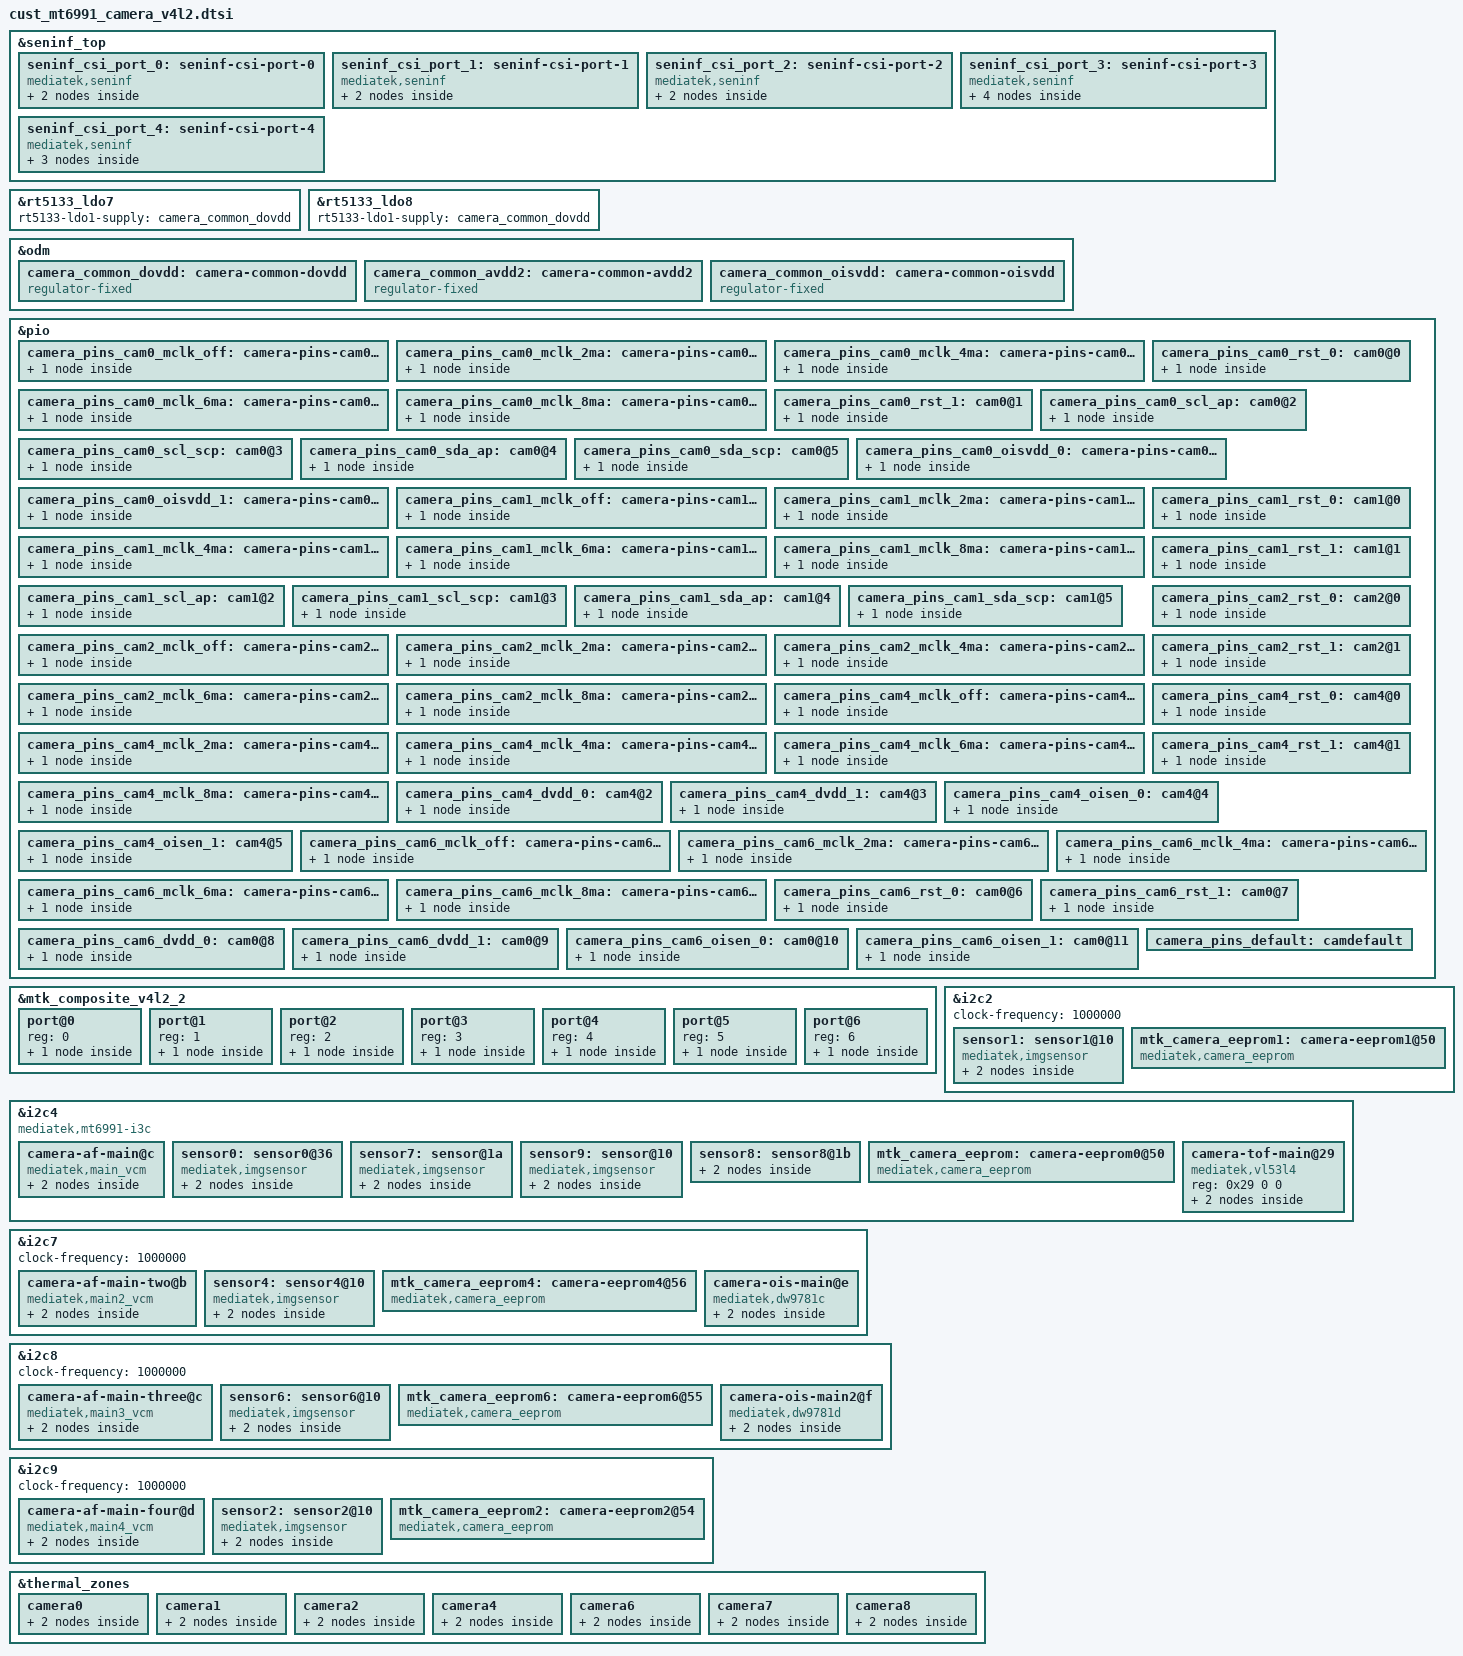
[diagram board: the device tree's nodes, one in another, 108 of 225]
// SPDX-License-Identifier: GPL-2.0
/* Copyright (c) 2023 MediaTek Inc. */
#include <dt-bindings/clock/mt6991-clk.h>

&seninf_top {
		seninf_csi_port_0: seninf-csi-port-0 {
			compatible = "mediatek,seninf";
			csi-port = "0";

			nvmem-cells = <&csi_efuse0>;
			nvmem-cell-names = "rg_csi";

			port {
				seninf_csi_port_0_in: endpoint {
					remote-endpoint = <&sensor1_out>;
				};
			};
		};

		seninf_csi_port_1: seninf-csi-port-1 {
			compatible = "mediatek,seninf";
			csi-port = "1";

			nvmem-cells = <&csi_efuse1>;
			nvmem-cell-names = "rg_csi";

			port {
				seninf_csi_port_1_in: endpoint {
					remote-endpoint = <&sensor6_out>;
				};
			};
		};

		seninf_csi_port_2: seninf-csi-port-2 {
			compatible = "mediatek,seninf";
			csi-port = "2";

			nvmem-cells = <&csi_efuse2>;
			nvmem-cell-names = "rg_csi";

			port {
				seninf_csi_port_2_in: endpoint {
					remote-endpoint = <&sensor4_out>;
				};
			};
		};
		seninf_csi_port_3: seninf-csi-port-3 {
			compatible = "mediatek,seninf";
			csi-port = "3";

			nvmem-cells = <&csi_efuse3>;
			nvmem-cell-names = "rg_csi";

			port {
				seninf_csi_port_3_in_1: endpoint@1 {
					remote-endpoint = <&sensor0_out>;
				};
				seninf_csi_port_3_in_2: endpoint@2 {
					remote-endpoint = <&sensor7_out>;
				};
				seninf_csi_port_3_in_3: endpoint@3 {
					remote-endpoint = <&sensor9_out>;
				};
			};
		};
		seninf_csi_port_4: seninf-csi-port-4 {
			compatible = "mediatek,seninf";
			csi-port = "4";

			nvmem-cells = <&csi_efuse4>;
			nvmem-cell-names = "rg_csi";

			port {
				seninf_csi_port_4_in_1: endpoint@1 {
					remote-endpoint = <&sensor2_out>;
				};
				seninf_csi_port_4_in_2: endpoint@2 {
					remote-endpoint = <&sensor8_out>;
				};
			};
		};
};

&rt5133_ldo7 {
	rt5133-ldo1-supply = <&camera_common_dovdd>;
};

&rt5133_ldo8 {
	rt5133-ldo1-supply = <&camera_common_dovdd>;
};

/* CAMERA GPIO fixed to regulator */
&odm {
	camera_common_dovdd: camera-common-dovdd {
		compatible = "regulator-fixed";
		regulator-name = "camera-common-dovdd";
		regulator-min-microvolt = <1800000>;
		regulator-max-microvolt = <1800000>;
		enable-active-high;
		gpio = <&pio 213 0x0>;
	};
	camera_common_avdd2: camera-common-avdd2 {
		compatible = "regulator-fixed";
		regulator-name = "camera-common-avdd2";
		regulator-min-microvolt = <1800000>;
		regulator-max-microvolt = <1800000>;
		enable-active-high;
		/*gpio = <&pio 92 0x0>;*/
	};
	camera_common_oisvdd: camera-common-oisvdd {
		compatible = "regulator-fixed";
		regulator-name = "camera-common-oisvdd";
		regulator-min-microvolt = <1800000>;
		regulator-max-microvolt = <1800000>;
		enable-active-high;
		/*gpio = <&pio 113 0x0>;*/
	};
};

/* CAMERA GPIO standardization */
&pio {
	camera_pins_cam0_mclk_off: camera-pins-cam0-mclk-off {
		pins-cmd-dat {
			pinmux = <PINMUX_GPIO79__FUNC_GPIO79>;
			drive-strength = <1>;
		};
	};
	camera_pins_cam0_mclk_2ma: camera-pins-cam0-mclk-2ma {
		pins-cmd-dat {
			pinmux = <PINMUX_GPIO79__FUNC_CMMCLK0>;
			drive-strength = <0>;
		};
	};
	camera_pins_cam0_mclk_4ma: camera-pins-cam0-mclk-4ma {
		pins-cmd-dat {
			pinmux = <PINMUX_GPIO79__FUNC_CMMCLK0>;
			drive-strength = <1>;
		};
	};
	camera_pins_cam0_mclk_6ma: camera-pins-cam0-mclk-6ma {
		pins-cmd-dat {
			pinmux = <PINMUX_GPIO79__FUNC_CMMCLK0>;
			drive-strength = <2>;
		};
	};
	camera_pins_cam0_mclk_8ma: camera-pins-cam0-mclk-8ma {
		pins-cmd-dat {
			pinmux = <PINMUX_GPIO79__FUNC_CMMCLK0>;
			drive-strength = <3>;
		};
	};
	camera_pins_cam0_rst_0: cam0@0 {
		pins-cmd-dat {
			pinmux = <PINMUX_GPIO187__FUNC_GPIO187>;
			slew-rate = <1>;
			output-low;
		};
	};
	camera_pins_cam0_rst_1: cam0@1 {
		pins-cmd-dat {
			pinmux = <PINMUX_GPIO187__FUNC_GPIO187>;
			slew-rate = <1>;
			output-high;
		};
	};
	camera_pins_cam0_scl_ap: cam0@2 {
		pins-cmd-dat {
			pinmux = <PINMUX_GPIO190__FUNC_SCL4>;
		};
	};
	camera_pins_cam0_scl_scp: cam0@3 {
		pins-cmd-dat {
			pinmux = <PINMUX_GPIO190__FUNC_SCP_SCL9>;
		};
	};
	camera_pins_cam0_sda_ap: cam0@4 {
		pins-cmd-dat {
			pinmux = <PINMUX_GPIO191__FUNC_SDA4>;
		};
	};
	camera_pins_cam0_sda_scp: cam0@5 {
		pins-cmd-dat {
			pinmux = <PINMUX_GPIO191__FUNC_SCP_SDA9>;
		};
	};
	camera_pins_cam0_oisvdd_0: camera-pins-cam0-oisvdd-0 {
		pins-cmd-dat {
#if 0
			pinmux = <PINMUX_GPIO93__FUNC_GPIO93>;
			slew-rate = <1>;
			output-low;
#endif
		};
	};
	camera_pins_cam0_oisvdd_1: camera-pins-cam0-oisvdd-1 {
		pins-cmd-dat {
#if 0
			pinmux = <PINMUX_GPIO93__FUNC_GPIO93>;
			slew-rate = <1>;
			output-high;
#endif
		};
	};
	camera_pins_cam1_mclk_off: camera-pins-cam1-mclk-off {
		pins-cmd-dat {
			pinmux = <PINMUX_GPIO80__FUNC_GPIO80>;
			drive-strength = <1>;
		};
	};
	camera_pins_cam1_mclk_2ma: camera-pins-cam1-mclk-2ma {
		pins-cmd-dat {
			pinmux = <PINMUX_GPIO80__FUNC_CMMCLK1>;
			drive-strength = <0>;
		};
	};
	camera_pins_cam1_mclk_4ma: camera-pins-cam1-mclk-4ma {
		pins-cmd-dat {
			pinmux = <PINMUX_GPIO80__FUNC_CMMCLK1>;
			drive-strength = <1>;
		};
	};
	camera_pins_cam1_mclk_6ma: camera-pins-cam1-mclk-6ma {
		pins-cmd-dat {
			pinmux = <PINMUX_GPIO80__FUNC_CMMCLK1>;
			drive-strength = <2>;
		};
	};
	camera_pins_cam1_mclk_8ma: camera-pins-cam1-mclk-8ma {
		pins-cmd-dat {
			pinmux = <PINMUX_GPIO80__FUNC_CMMCLK1>;
			drive-strength = <3>;
		};
	};
	camera_pins_cam1_rst_0: cam1@0 {
		pins-cmd-dat {
			pinmux = <PINMUX_GPIO186__FUNC_GPIO186>;
			slew-rate = <1>;
			output-low;
		};
	};
	camera_pins_cam1_rst_1: cam1@1 {
		pins-cmd-dat {
			pinmux = <PINMUX_GPIO186__FUNC_GPIO186>;
			slew-rate = <1>;
			output-high;
		};
	};
	camera_pins_cam1_scl_ap: cam1@2 {
		pins-cmd-dat {
			pinmux = <PINMUX_GPIO188__FUNC_SCL2>;
		};
	};
	camera_pins_cam1_scl_scp: cam1@3 {
		pins-cmd-dat {
			pinmux = <PINMUX_GPIO188__FUNC_SCP_SCL8>;
		};
	};
	camera_pins_cam1_sda_ap: cam1@4 {
		pins-cmd-dat {
			pinmux = <PINMUX_GPIO189__FUNC_SDA2>;
		};
	};
	camera_pins_cam1_sda_scp: cam1@5 {
		pins-cmd-dat {
			pinmux = <PINMUX_GPIO189__FUNC_SCP_SDA8>;
		};
	};
	camera_pins_cam2_mclk_off: camera-pins-cam2-mclk-off {
		pins-cmd-dat {
			pinmux = <PINMUX_GPIO210__FUNC_GPIO210>;
			drive-strength = <1>;
		};
	};
	camera_pins_cam2_mclk_2ma: camera-pins-cam2-mclk-2ma {
		pins-cmd-dat {
			pinmux = <PINMUX_GPIO210__FUNC_CMMCLK4>;
			drive-strength = <0>;
		};
	};
	camera_pins_cam2_mclk_4ma: camera-pins-cam2-mclk-4ma {
		pins-cmd-dat {
			pinmux = <PINMUX_GPIO210__FUNC_CMMCLK4>;
			drive-strength = <1>;
		};
	};
	camera_pins_cam2_mclk_6ma: camera-pins-cam2-mclk-6ma {
		pins-cmd-dat {
			pinmux = <PINMUX_GPIO210__FUNC_CMMCLK4>;
			drive-strength = <2>;
		};
	};
	camera_pins_cam2_mclk_8ma: camera-pins-cam2-mclk-8ma {
		pins-cmd-dat {
			pinmux = <PINMUX_GPIO210__FUNC_CMMCLK4>;
			drive-strength = <3>;
		};
	};
	camera_pins_cam2_rst_0: cam2@0 {
		pins-cmd-dat {
#if 0
			pinmux = <PINMUX_GPIO206__FUNC_GPIO206>;
			slew-rate = <1>;
			output-low;
#endif
		};
	};
	camera_pins_cam2_rst_1: cam2@1 {
		pins-cmd-dat {
#if 0
			pinmux = <PINMUX_GPIO206__FUNC_GPIO206>;
			slew-rate = <1>;
			output-high;
#endif
		};
	};
#if 0
	camera_pins_cam2_mclk1_off: camera-pins-cam2-mclk1-off {
		pins-cmd-dat {
			pinmux = <PINMUX_GPIO124__FUNC_GPIO124>;
			drive-strength = <1>;
		};
	};
	camera_pins_cam2_mclk1_2ma: camera-pins-cam2-mclk1-2ma {
		pins-cmd-dat {
			pinmux = <PINMUX_GPIO124__FUNC_CMMCLK0>;
			drive-strength = <0>;
		};
	};
	camera_pins_cam2_mclk1_4ma: camera-pins-cam2-mclk1-4ma {
		pins-cmd-dat {
			pinmux = <PINMUX_GPIO124__FUNC_CMMCLK0>;
			drive-strength = <1>;
		};
	};
	camera_pins_cam2_mclk1_6ma: camera-pins-cam2-mclk1-6ma {
		pins-cmd-dat {
			pinmux = <PINMUX_GPIO124__FUNC_CMMCLK0>;
			drive-strength = <2>;
		};
	};
	camera_pins_cam2_mclk1_8ma: camera-pins-cam2-mclk1-8ma {
		pins-cmd-dat {
			pinmux = <PINMUX_GPIO124__FUNC_CMMCLK0>;
			drive-strength = <3>;
		};
	};
	camera_pins_cam2_rst1_0: cam2@2 {
		pins-cmd-dat {
			pinmux = <PINMUX_GPIO160__FUNC_GPIO160>;
			slew-rate = <1>;
			output-low;
		};
	};
	camera_pins_cam2_rst1_1: cam2@3 {
		pins-cmd-dat {
			pinmux = <PINMUX_GPIO160__FUNC_GPIO160>;
			slew-rate = <1>;
			output-high;
		};
	};
	camera_pins_cam2_ponv_0: cam2@4 {
		pins-cmd-dat {
			pinmux = <PINMUX_GPIO159__FUNC_GPIO159>;
			slew-rate = <1>;
			output-low;
		};
	};
	camera_pins_cam2_ponv_1: cam2@5 {
		pins-cmd-dat {
			pinmux = <PINMUX_GPIO159__FUNC_GPIO159>;
			slew-rate = <1>;
			output-high;
		};
	};
	camera_pins_cam2_scl_ap: cam2@6 {
		pins-cmd-dat {
			pinmux = <PINMUX_GPIO104__FUNC_SCL13>;
		};
	};
	camera_pins_cam2_scl_scp: cam2@7 {
		pins-cmd-dat {
			pinmux = <PINMUX_GPIO104__FUNC_SCP_SCL3>;
		};
	};
	camera_pins_cam2_sda_ap: cam2@8 {
		pins-cmd-dat {
			pinmux = <PINMUX_GPIO105__FUNC_SDA13>;
		};
	};
	camera_pins_cam2_sda_scp: cam2@9 {
		pins-cmd-dat {
			pinmux = <PINMUX_GPIO105__FUNC_SCP_SDA3>;
		};
	};
	camera_pins_cam2_eint: cam2@10 {
		pins-cmd-dat {
			pinmux = <PINMUX_GPIO109__FUNC_GPIO109>;
			bias-pull-up;
			input-enable;
		};
	};
#endif
	camera_pins_cam4_mclk_off: camera-pins-cam4-mclk-off {
		pins-cmd-dat {
			pinmux = <PINMUX_GPIO192__FUNC_GPIO192>;
			drive-strength = <1>;
		};
	};
	camera_pins_cam4_mclk_2ma: camera-pins-cam4-mclk-2ma {
		pins-cmd-dat {
			pinmux = <PINMUX_GPIO192__FUNC_CMMCLK2>;
			drive-strength = <0>;
		};
	};
	camera_pins_cam4_mclk_4ma: camera-pins-cam4-mclk-4ma {
		pins-cmd-dat {
			pinmux = <PINMUX_GPIO192__FUNC_CMMCLK2>;
			drive-strength = <1>;
		};
	};
	camera_pins_cam4_mclk_6ma: camera-pins-cam4-mclk-6ma {
		pins-cmd-dat {
			pinmux = <PINMUX_GPIO192__FUNC_CMMCLK2>;
			drive-strength = <2>;
		};
	};
	camera_pins_cam4_mclk_8ma: camera-pins-cam4-mclk-8ma {
		pins-cmd-dat {
			pinmux = <PINMUX_GPIO192__FUNC_CMMCLK2>;
			drive-strength = <3>;
		};
	};
	camera_pins_cam4_rst_0: cam4@0 {
		pins-cmd-dat {
#if 0
			pinmux = <PINMUX_GPIO193__FUNC_GPIO193>;
			slew-rate = <1>;
			output-low;
#endif
		};
	};
	camera_pins_cam4_rst_1: cam4@1 {
		pins-cmd-dat {
#if 0
			pinmux = <PINMUX_GPIO193__FUNC_GPIO193>;
			slew-rate = <1>;
			output-high;
#endif
		};
	};
	camera_pins_cam4_dvdd_0: cam4@2 {
		pins-cmd-dat {
#if 0
			pinmux = <PINMUX_GPIO112__FUNC_GPIO112>;
			slew-rate = <1>;
			output-low;
#endif
		};
	};
	camera_pins_cam4_dvdd_1: cam4@3 {
		pins-cmd-dat {
#if 0
			pinmux = <PINMUX_GPIO112__FUNC_GPIO112>;
			slew-rate = <1>;
			output-high;
#endif
		};
	};
	camera_pins_cam4_oisen_0: cam4@4 {
		pins-cmd-dat {
#if 0
			pinmux = <PINMUX_GPIO212__FUNC_GPIO212>;
			slew-rate = <1>;
			output-low;
#endif
		};
	};
	camera_pins_cam4_oisen_1: cam4@5 {
		pins-cmd-dat {
#if 0
			pinmux = <PINMUX_GPIO212__FUNC_GPIO212>;
			slew-rate = <1>;
			output-high;
#endif
		};
	};
	camera_pins_cam6_mclk_off: camera-pins-cam6-mclk-off {
		pins-cmd-dat {
			pinmux = <PINMUX_GPIO196__FUNC_GPIO196>;
			drive-strength = <1>;
		};
	};
	camera_pins_cam6_mclk_2ma: camera-pins-cam6-mclk-2ma {
		pins-cmd-dat {
			pinmux = <PINMUX_GPIO196__FUNC_CMMCLK3>;
			drive-strength = <0>;
		};
	};
	camera_pins_cam6_mclk_4ma: camera-pins-cam6-mclk-4ma {
		pins-cmd-dat {
			pinmux = <PINMUX_GPIO196__FUNC_CMMCLK3>;
			drive-strength = <1>;
		};
	};
	camera_pins_cam6_mclk_6ma: camera-pins-cam6-mclk-6ma {
		pins-cmd-dat {
			pinmux = <PINMUX_GPIO196__FUNC_CMMCLK3>;
			drive-strength = <2>;
		};
	};
	camera_pins_cam6_mclk_8ma: camera-pins-cam6-mclk-8ma {
		pins-cmd-dat {
			pinmux = <PINMUX_GPIO196__FUNC_CMMCLK3>;
			drive-strength = <3>;
		};
	};
	camera_pins_cam6_rst_0: cam0@6 {
		pins-cmd-dat {
#if 0
			pinmux = <PINMUX_GPIO197__FUNC_GPIO197>;
			slew-rate = <1>;
			output-low;
#endif
		};
	};
	camera_pins_cam6_rst_1: cam0@7 {
		pins-cmd-dat {
#if 0
			pinmux = <PINMUX_GPIO197__FUNC_GPIO197>;
			slew-rate = <1>;
			output-high;
#endif
		};
	};
	camera_pins_cam6_dvdd_0: cam0@8 {
		pins-cmd-dat {
#if 0
			pinmux = <PINMUX_GPIO111__FUNC_GPIO111>;
			slew-rate = <1>;
			output-low;
#endif
		};
	};
	camera_pins_cam6_dvdd_1: cam0@9 {
		pins-cmd-dat {
#if 0
			pinmux = <PINMUX_GPIO111__FUNC_GPIO111>;
			slew-rate = <1>;
			output-high;
#endif
		};
	};
	camera_pins_cam6_oisen_0: cam0@10 {
		pins-cmd-dat {
#if 0
			pinmux = <PINMUX_GPIO185__FUNC_GPIO185>;
			slew-rate = <1>;
			output-low;
#endif
		};
	};
	camera_pins_cam6_oisen_1: cam0@11 {
		pins-cmd-dat {
#if 0
			pinmux = <PINMUX_GPIO185__FUNC_GPIO185>;
			slew-rate = <1>;
			output-high;
#endif
		};
	};
	camera_pins_default: camdefault {
	};
};
/* CAMERA GPIO end */
&mtk_composite_v4l2_2 {
	#address-cells = <1>;
	#size-cells = <0>;
	port@0 {
		reg = <0>;
		main_af_endpoint: endpoint {
			remote-endpoint = <&main_af>;
		};
	};
	port@1 {
		reg = <1>;
		main_af_cam1_endpoint: endpoint {
			remote-endpoint = <&main_af_cam1>;
		};
	};
	port@2 {
		reg = <2>;
		main_af_cam2_endpoint: endpoint {
			remote-endpoint = <&main_af_cam2>;
		};
	};
	port@3 {
		reg = <3>;
		main_af_cam3_endpoint: endpoint {
			remote-endpoint = <&main_af_cam3>;
		};
	};
	port@4 {
		reg = <4>;
		main_ois_cam1_endpoint: endpoint {
			remote-endpoint = <&main_ois_cam1>;
		};
	};
	port@5 {
		reg = <5>;
		main_ois_cam2_endpoint: endpoint {
			remote-endpoint = <&main_ois_cam2>;
		};
	};
	port@6 {
		reg = <6>;
		main_tof_endpoint: endpoint {
			remote-endpoint = <&main_tof>;
		};
	};
};

&i2c2 {
	status = "okay";
	clock-frequency = <1000000>;

	sensor1: sensor1@10 {
		compatible = "mediatek,imgsensor";
		sensor-names = "s5k3p9sp_mipi_raw";
		reg = <0x10>;
		maximum-pmic-delay = <4000>;

		#thermal-sensor-cells = <0>;

		pinctrl-names = "mclk_off",
				"mclk_2mA",
				"mclk_4mA",
				"mclk_6mA",
				"mclk_8mA",
				"rst_low",
				"rst_high",
				"scl_ap",
				"scl_scp",
				"sda_ap",
				"sda_scp";
		pinctrl-0 = <&camera_pins_cam1_mclk_off>;
		pinctrl-1 = <&camera_pins_cam1_mclk_2ma>;
		pinctrl-2 = <&camera_pins_cam1_mclk_4ma>;
		pinctrl-3 = <&camera_pins_cam1_mclk_6ma>;
		pinctrl-4 = <&camera_pins_cam1_mclk_8ma>;
		pinctrl-5 = <&camera_pins_cam1_rst_0>;
		pinctrl-6 = <&camera_pins_cam1_rst_1>;
		pinctrl-7 = <&camera_pins_cam1_scl_ap>;
		pinctrl-8 = <&camera_pins_cam1_scl_scp>;
		pinctrl-9 = <&camera_pins_cam1_sda_ap>;
		pinctrl-10 = <&camera_pins_cam1_sda_scp>;

		avdd-supply = <&rt5133_ldo3>;
		dvdd1-supply = <&rt5133_gpio3>;
		dovdd-supply = <&camera_common_dovdd>;
		base-supply = <&rt5133_base>;

		clocks = <&cksys_clk CLK_CK_UNIVPLL_192M_D32>,
			<&cksys_clk CLK_CK_UNIVPLL_192M_D16>,
			<&cksys_clk CLK_CK_F26M_CK_D2>,
			<&cksys_clk CLK_CK_UNIVPLL_192M_D10>,
			<&cksys_clk CLK_CK_UNIVPLL_192M_D8>,
			<&cksys_clk CLK_CK_UNIVPLL_D6_D16>,
			<&cksys_clk CLK_CK_OSC3>,
			<&cksys_clk CLK_CK_UNIVPLL_D6_D8>,
			<&vlp_cksys_clk CLK_VLP_CK_CAMTG1_SEL>;
		clock-names = "6", "12", "13", "19.2", "24", "26", "26_ulposc", "52", "mclk";

		status = "okay";
		port {
			sensor1_out: endpoint {
				remote-endpoint = <&seninf_csi_port_0_in>;
			};
		};
	};

	mtk_camera_eeprom1:camera-eeprom1@50 {
		compatible = "mediatek,camera_eeprom";
		reg = <0x50 0 0>;
		names = "s5k3p9sp_mtk_eeprom";
		status = "okay";
	};
};

&i2c4 {
	compatible = "mediatek,mt6991-i3c";
	#address-cells = <1>;
	#size-cells = <2>;
	status = "okay";

	camera-af-main@c {
		compatible = "mediatek,main_vcm";
		reg = <0x0c 0 0>;
		vin-supply = <&rt5133_gpio1>;
		port {
			main_af: endpoint {
				remote-endpoint = <&main_af_endpoint>;
			};
		};
	};

	sensor0: sensor0@36 {
		compatible = "mediatek,imgsensor";
		sensor-names = "ov48b_mipi_raw",
					"imx06a_mipi_raw";
		reg = <0x36 0 0>;
		maximum-pmic-delay = <4000>;

		#thermal-sensor-cells = <0>;

		pinctrl-names = "mclk_off",
				"mclk_2mA",
				"mclk_4mA",
				"mclk_6mA",
				"mclk_8mA",
				"rst_low",
				"rst_high",
				"scl_ap",
				"scl_scp",
				"sda_ap",
				"sda_scp",
				"oisvdd_off",
				"oisvdd_on";
		pinctrl-0 = <&camera_pins_cam0_mclk_off>;
		pinctrl-1 = <&camera_pins_cam0_mclk_2ma>;
		pinctrl-2 = <&camera_pins_cam0_mclk_4ma>;
		pinctrl-3 = <&camera_pins_cam0_mclk_6ma>;
		pinctrl-4 = <&camera_pins_cam0_mclk_8ma>;
		pinctrl-5 = <&camera_pins_cam0_rst_0>;
		pinctrl-6 = <&camera_pins_cam0_rst_1>;
		pinctrl-7 = <&camera_pins_cam0_scl_ap>;
		pinctrl-8 = <&camera_pins_cam0_scl_scp>;
		pinctrl-9 = <&camera_pins_cam0_sda_ap>;
		pinctrl-10 = <&camera_pins_cam0_sda_scp>;
		pinctrl-11 = <&camera_pins_cam0_oisvdd_0>;
		pinctrl-12 = <&camera_pins_cam0_oisvdd_1>;

		avdd-supply = <&rt5133_ldo5>;
		avdd2-supply = <&camera_common_avdd2>;
		dvdd-supply = <&rt5133_ldo8>;
		afvdd1-supply = <&rt5133_gpio1>;
		dovdd-supply = <&camera_common_dovdd>;
		base-supply = <&rt5133_base>;

		clocks = <&cksys_clk CLK_CK_UNIVPLL_192M_D32>,
			<&cksys_clk CLK_CK_UNIVPLL_192M_D16>,
			<&cksys_clk CLK_CK_F26M_CK_D2>,
			<&cksys_clk CLK_CK_UNIVPLL_192M_D10>,
			<&cksys_clk CLK_CK_UNIVPLL_192M_D8>,
			<&cksys_clk CLK_CK_UNIVPLL_D6_D16>,
			<&cksys_clk CLK_CK_OSC3>,
			<&cksys_clk CLK_CK_UNIVPLL_D6_D8>,
			<&vlp_cksys_clk CLK_VLP_CK_CAMTG0_SEL>;
		clock-names = "6", "12", "13", "19.2", "24", "26", "26_ulposc", "52", "mclk";

		status = "okay";
		port {
			sensor0_out: endpoint {
				remote-endpoint = <&seninf_csi_port_3_in_1>;
			};
		};
	};

	sensor7: sensor@1a {
		compatible = "mediatek,imgsensor";
		sensor-names = "imx989_mipi_raw";
		reindex-match = "imx989_mipi_raw";
		reg = <0x1a 0 0>;
		maximum-pmic-delay = <4000>;
		reindex-to = <0>;

		#thermal-sensor-cells = <0>;

		pinctrl-names = "mclk_off",
				"mclk_2mA",
				"mclk_4mA",
				"mclk_6mA",
				"mclk_8mA",
				"rst_low",
				"rst_high",
				"scl_ap",
				"scl_scp",
				"sda_ap",
				"sda_scp",
				"oisvdd_off",
				"oisvdd_on";
		pinctrl-0 = <&camera_pins_cam0_mclk_off>;
		pinctrl-1 = <&camera_pins_cam0_mclk_2ma>;
		pinctrl-2 = <&camera_pins_cam0_mclk_4ma>;
		pinctrl-3 = <&camera_pins_cam0_mclk_6ma>;
		pinctrl-4 = <&camera_pins_cam0_mclk_8ma>;
		pinctrl-5 = <&camera_pins_cam0_rst_0>;
		pinctrl-6 = <&camera_pins_cam0_rst_1>;
		pinctrl-7 = <&camera_pins_cam0_scl_ap>;
		pinctrl-8 = <&camera_pins_cam0_scl_scp>;
		pinctrl-9 = <&camera_pins_cam0_sda_ap>;
		pinctrl-10 = <&camera_pins_cam0_sda_scp>;
		pinctrl-11 = <&camera_pins_cam0_oisvdd_0>;
		pinctrl-12 = <&camera_pins_cam0_oisvdd_1>;

		avdd-supply = <&rt5133_ldo5>;
		avdd2-supply = <&camera_common_avdd2>;
		dvdd-supply = <&rt5133_ldo8>;
		afvdd1-supply = <&rt5133_gpio1>;
		dovdd-supply = <&camera_common_dovdd>;
		base-supply = <&rt5133_base>;

		clocks = <&cksys_clk CLK_CK_UNIVPLL_192M_D32>,
			<&cksys_clk CLK_CK_UNIVPLL_192M_D16>,
			<&cksys_clk CLK_CK_F26M_CK_D2>,
			<&cksys_clk CLK_CK_UNIVPLL_192M_D10>,
			<&cksys_clk CLK_CK_UNIVPLL_192M_D8>,
			<&cksys_clk CLK_CK_UNIVPLL_D6_D16>,
			<&cksys_clk CLK_CK_UNIVPLL_D6_D8>,
			<&vlp_cksys_clk CLK_VLP_CK_CAMTG0_SEL>;
		clock-names = "6", "12", "13", "19.2", "24", "26", "52", "mclk";

		status = "okay";
		port {
			sensor7_out: endpoint {
				remote-endpoint = <&seninf_csi_port_3_in_2>;
			};
		};
	};

	sensor9: sensor@10 {
		compatible = "mediatek,imgsensor";
		sensor-names = "s5khp3sp_mipi_raw";
		reindex-match = "s5khp3sp_mipi_raw";
		reg = <0x10 0 0>;
		maximum-pmic-delay = <4000>;
		reindex-to = <0>;

		#thermal-sensor-cells = <0>;

		pinctrl-names = "mclk_off",
				"mclk_2mA",
				"mclk_4mA",
				"mclk_6mA",
				"mclk_8mA",
				"rst_low",
				"rst_high",
				"scl_ap",
				"scl_scp",
				"sda_ap",
				"sda_scp",
				"oisvdd_off",
				"oisvdd_on";
		pinctrl-0 = <&camera_pins_cam0_mclk_off>;
		pinctrl-1 = <&camera_pins_cam0_mclk_2ma>;
		pinctrl-2 = <&camera_pins_cam0_mclk_4ma>;
		pinctrl-3 = <&camera_pins_cam0_mclk_6ma>;
		pinctrl-4 = <&camera_pins_cam0_mclk_8ma>;
		pinctrl-5 = <&camera_pins_cam0_rst_0>;
		pinctrl-6 = <&camera_pins_cam0_rst_1>;
		pinctrl-7 = <&camera_pins_cam0_scl_ap>;
		pinctrl-8 = <&camera_pins_cam0_scl_scp>;
		pinctrl-9 = <&camera_pins_cam0_sda_ap>;
		pinctrl-10 = <&camera_pins_cam0_sda_scp>;
		pinctrl-11 = <&camera_pins_cam0_oisvdd_0>;
		pinctrl-12 = <&camera_pins_cam0_oisvdd_1>;

		avdd-supply = <&rt5133_ldo5>;
		avdd2-supply = <&camera_common_avdd2>;
		dvdd-supply = <&rt5133_ldo8>;
		afvdd1-supply = <&rt5133_gpio1>;
		dovdd-supply = <&camera_common_dovdd>;
		base-supply = <&rt5133_base>;

		clocks = <&cksys_clk CLK_CK_UNIVPLL_192M_D32>,
			<&cksys_clk CLK_CK_UNIVPLL_192M_D16>,
			<&cksys_clk CLK_CK_F26M_CK_D2>,
			<&cksys_clk CLK_CK_UNIVPLL_192M_D10>,
			<&cksys_clk CLK_CK_UNIVPLL_192M_D8>,
			<&cksys_clk CLK_CK_UNIVPLL_D6_D16>,
			<&cksys_clk CLK_CK_UNIVPLL_D6_D8>,
			<&vlp_cksys_clk CLK_VLP_CK_CAMTG0_SEL>;
		clock-names = "6", "12", "13", "19.2", "24", "26", "52", "mclk";

		status = "okay";
		port {
			sensor9_out: endpoint {
				remote-endpoint = <&seninf_csi_port_3_in_3>;
			};
		};
	};

	sensor8: sensor8@1b {
		sensor-names = "imx866rgb_mipi_raw";
		reg = <0x1b 0x0360 0x08660000>;
		assigned-address = <0x25>;
		reindex-match = "imx866rgb_mipi_raw";
		reindex-to = <0>;
		maximum-pmic-delay = <4000>;
		#thermal-sensor-cells = <0>;

		pinctrl-names = "mclk_off",
				"mclk_2mA",
				"mclk_4mA",
				"mclk_6mA",
				"mclk_8mA",
				"rst_low",
				"rst_high";
		pinctrl-0 = <&camera_pins_cam2_mclk_off>;
		pinctrl-1 = <&camera_pins_cam2_mclk_2ma>;
		pinctrl-2 = <&camera_pins_cam2_mclk_4ma>;
		pinctrl-3 = <&camera_pins_cam2_mclk_6ma>;
		pinctrl-4 = <&camera_pins_cam2_mclk_8ma>;
		pinctrl-5 = <&camera_pins_cam2_rst_0>;
		pinctrl-6 = <&camera_pins_cam2_rst_1>;

		avdd-supply = <&rt5133_ldo6>; // AVDD for imx598/imx709
		avdd3-supply = <&camera_common_avdd2>; // AVDD2 for imx866
		avdd4-supply = <&rt5133_gpio2>; // AVDD2 for imx598
		dvdd-supply = <&rt5133_ldo7>; // DVDD for imx598
		dvdd2-supply = <&rt5133_ldo8>; // DVDD for imx709
		afvdd-supply = <&rt5133_ldo2>;
		dovdd-supply = <&camera_common_dovdd>;
		base-supply = <&rt5133_base>;

		clocks = <&cksys_clk CLK_CK_UNIVPLL_192M_D32>,
			<&cksys_clk CLK_CK_UNIVPLL_192M_D16>,
			<&cksys_clk CLK_CK_F26M_CK_D2>,
			<&cksys_clk CLK_CK_UNIVPLL_192M_D10>,
			<&cksys_clk CLK_CK_UNIVPLL_192M_D8>,
			<&cksys_clk CLK_CK_UNIVPLL_D6_D16>,
			<&cksys_clk CLK_CK_UNIVPLL_D6_D8>,
			<&vlp_cksys_clk CLK_VLP_CK_CAMTG4_SEL>;
		clock-names = "6", "12", "13", "19.2", "24", "26", "52", "mclk";
		status = "okay";
		port {
			sensor8_out: endpoint {
				remote-endpoint = <&seninf_csi_port_4_in_2>;
			};
		};
	};

	mtk_camera_eeprom:camera-eeprom0@50 {
		compatible = "mediatek,camera_eeprom";
		reg = <0x50 0 0>;
		names = "imx989_cust_eeprom",
				"ov48b_mtk_eeprom";
		status = "okay";
	};

	camera-tof-main@29 {
		compatible = "mediatek,vl53l4";
		reg = <0x29 0 0>;
		port {
			main_tof: endpoint {
				remote-endpoint = <&main_tof_endpoint>;
			};
		};
	};
};

&i2c7 {
	status = "okay";
	clock-frequency = <1000000>;

	camera-af-main-two@b {
		compatible = "mediatek,main2_vcm";
		reg = <0x0b>;
		vin-supply = <&rt5133_ldo2>;
		port {
			main_af_cam1: endpoint {
				remote-endpoint = <&main_af_cam1_endpoint>;
			};
		};
	};

	sensor4: sensor4@10 {
		compatible = "mediatek,imgsensor";
		sensor-names = "imx758_mipi_raw",
					"imx858_mipi_raw";
		reg = <0x10>;
		maximum-pmic-delay = <4000>;

		#thermal-sensor-cells = <0>;

		pinctrl-names = "mclk_off",
				"mclk_2mA",
				"mclk_4mA",
				"mclk_6mA",
				"mclk_8mA",
				"rst_low",
				"rst_high",
				"dvdd_off",
				"dvdd_on",
				"oisen_off",
				"oisen_on";
		pinctrl-0 = <&camera_pins_cam4_mclk_off>;
		pinctrl-1 = <&camera_pins_cam4_mclk_2ma>;
		pinctrl-2 = <&camera_pins_cam4_mclk_4ma>;
		pinctrl-3 = <&camera_pins_cam4_mclk_6ma>;
		pinctrl-4 = <&camera_pins_cam4_mclk_8ma>;
		pinctrl-5 = <&camera_pins_cam4_rst_0>;
		pinctrl-6 = <&camera_pins_cam4_rst_1>;
		pinctrl-7 = <&camera_pins_cam4_dvdd_0>;
		pinctrl-8 = <&camera_pins_cam4_dvdd_1>;
		pinctrl-9 = <&camera_pins_cam4_oisen_0>;
		pinctrl-10 = <&camera_pins_cam4_oisen_1>;

		avdd-supply = <&rt5133_ldo3>;
		afvdd-supply = <&rt5133_ldo2>;
		dovdd-supply = <&camera_common_dovdd>;
		oisvdd-supply = <&rt5133_ldo1>;
		base-supply = <&rt5133_base>;

		clocks = <&cksys_clk CLK_CK_UNIVPLL_192M_D32>,
			<&cksys_clk CLK_CK_UNIVPLL_192M_D16>,
			<&cksys_clk CLK_CK_F26M_CK_D2>,
			<&cksys_clk CLK_CK_UNIVPLL_192M_D10>,
			<&cksys_clk CLK_CK_UNIVPLL_192M_D8>,
			<&cksys_clk CLK_CK_UNIVPLL_D6_D16>,
			<&cksys_clk CLK_CK_OSC3>,
			<&cksys_clk CLK_CK_UNIVPLL_D6_D8>,
			<&vlp_cksys_clk CLK_VLP_CK_CAMTG2_SEL>;
		clock-names = "6", "12", "13", "19.2", "24", "26", "26_ulposc", "52", "mclk";

		status = "okay";
		port {
			sensor4_out: endpoint {
				remote-endpoint = <&seninf_csi_port_2_in>;
			};
		};
	};

	mtk_camera_eeprom4:camera-eeprom4@56 {
		compatible = "mediatek,camera_eeprom";
		reg = <0x56>;
		names = "imx758_cust_eeprom";
		status = "okay";
	};

	/* ois */
	camera-ois-main@e {
		compatible = "mediatek,dw9781c";
		reg = <0x0e>;
		vdd-supply = <&rt5133_ldo1>;
		rst-supply = <&camera_common_dovdd>;
		port {
			main_ois_cam1: endpoint {
				remote-endpoint = <&main_ois_cam1_endpoint>;
			};
		};
	};
};

&i2c8 {
	status = "okay";
	clock-frequency = <1000000>;

	camera-af-main-three@c {
		compatible = "mediatek,main3_vcm";
		reg = <0x0c>;
		vin-supply = <&rt5133_gpio1>;
		port {
			main_af_cam2: endpoint {
				remote-endpoint = <&main_af_cam2_endpoint>;
			};
		};
	};

	sensor6: sensor6@10 {
		compatible = "mediatek,imgsensor";
		sensor-names = "ov64b_mipi_raw";
		reg = <0x10>;
		maximum-pmic-delay = <4000>;

		#thermal-sensor-cells = <0>;

		pinctrl-names = "mclk_off",
				"mclk_2mA",
				"mclk_4mA",
				"mclk_6mA",
				"mclk_8mA",
				"rst_low",
				"rst_high",
				"dvdd_off",
				"dvdd_on",
				"oisen_off",
				"oisen_on";
		pinctrl-0 = <&camera_pins_cam6_mclk_off>;
		pinctrl-1 = <&camera_pins_cam6_mclk_2ma>;
		pinctrl-2 = <&camera_pins_cam6_mclk_4ma>;
		pinctrl-3 = <&camera_pins_cam6_mclk_6ma>;
		pinctrl-4 = <&camera_pins_cam6_mclk_8ma>;
		pinctrl-5 = <&camera_pins_cam6_rst_0>;
		pinctrl-6 = <&camera_pins_cam6_rst_1>;
		pinctrl-7 = <&camera_pins_cam6_dvdd_0>;
		pinctrl-8 = <&camera_pins_cam6_dvdd_1>;
		pinctrl-9 = <&camera_pins_cam6_oisen_0>;
		pinctrl-10 = <&camera_pins_cam6_oisen_1>;

		avdd-supply = <&rt5133_ldo4>;
		afvdd1-supply = <&rt5133_gpio1>;
		dovdd-supply = <&camera_common_dovdd>;
		oisvdd-supply = <&camera_common_oisvdd>;
		base-supply = <&rt5133_base>;

		clocks = <&cksys_clk CLK_CK_UNIVPLL_192M_D32>,
			<&cksys_clk CLK_CK_UNIVPLL_192M_D16>,
			<&cksys_clk CLK_CK_F26M_CK_D2>,
			<&cksys_clk CLK_CK_UNIVPLL_192M_D10>,
			<&cksys_clk CLK_CK_UNIVPLL_192M_D8>,
			<&cksys_clk CLK_CK_UNIVPLL_D6_D16>,
			<&cksys_clk CLK_CK_OSC3>,
			<&cksys_clk CLK_CK_UNIVPLL_D6_D8>,
			<&vlp_cksys_clk CLK_VLP_CK_CAMTG3_SEL>;
		clock-names = "6", "12", "13", "19.2", "24", "26", "26_ulposc", "52", "mclk";

		status = "okay";
		port {
			sensor6_out: endpoint {
				remote-endpoint = <&seninf_csi_port_1_in>;
			};
		};
	};

	mtk_camera_eeprom6:camera-eeprom6@55 {
		compatible = "mediatek,camera_eeprom";
		reg = <0x55>;
		names = "ov64b_cust_eeprom";
		status = "okay";
	};

	/* ois */
	camera-ois-main2@f {
		compatible = "mediatek,dw9781d";
		reg = <0x0f>;
		vdd-supply = <&camera_common_oisvdd>;
		rst-supply = <&camera_common_dovdd>;
		port {
			main_ois_cam2: endpoint {
				remote-endpoint = <&main_ois_cam2_endpoint>;
			};
		};
	};
};

&i2c9 {
	status = "okay";
	clock-frequency = <1000000>;

	camera-af-main-four@d {
		compatible = "mediatek,main4_vcm";
		reg = <0x0d>;
		vin-supply = <&rt5133_ldo2>;
		port {
			main_af_cam3: endpoint {
				remote-endpoint = <&main_af_cam3_endpoint>;
			};
		};
	};

	sensor2: sensor2@10 {
		compatible = "mediatek,imgsensor";
		sensor-names = "imx598_mipi_raw",
				"imx709_mipi_raw",
				"imx858dual_mipi_raw";
		reg = <0x10>;
		maximum-pmic-delay = <4000>;
		reindex-match = "imx709_mipi_raw";
		reindex-to = <0>;

		cust-aov-csi-clk = <312>;

		#thermal-sensor-cells = <0>;

		pinctrl-names = "mclk_off",
				"mclk_2mA",
				"mclk_4mA",
				"mclk_6mA",
				"mclk_8mA",
				"rst_low",
				"rst_high";
#if 0
				"mclk1_off",
				"mclk1_2mA",
				"mclk1_4mA",
				"mclk1_6mA",
				"mclk1_8mA",
				"rst1_low",
				"rst1_high",
				"ponv_low",
				"ponv_high",
				"scl_ap",
				"scl_scp",
				"sda_ap",
				"sda_scp",
				"eint";
#endif
		pinctrl-0 = <&camera_pins_cam2_mclk_off>;
		pinctrl-1 = <&camera_pins_cam2_mclk_2ma>;
		pinctrl-2 = <&camera_pins_cam2_mclk_4ma>;
		pinctrl-3 = <&camera_pins_cam2_mclk_6ma>;
		pinctrl-4 = <&camera_pins_cam2_mclk_8ma>;
		pinctrl-5 = <&camera_pins_cam2_rst_0>;
		pinctrl-6 = <&camera_pins_cam2_rst_1>;
#if 0
		pinctrl-7 = <&camera_pins_cam2_mclk1_off>;
		pinctrl-8 = <&camera_pins_cam2_mclk1_2ma>;
		pinctrl-9 = <&camera_pins_cam2_mclk1_4ma>;
		pinctrl-10 = <&camera_pins_cam2_mclk1_6ma>;
		pinctrl-11 = <&camera_pins_cam2_mclk1_8ma>;
		pinctrl-12 = <&camera_pins_cam2_rst1_0>;
		pinctrl-13 = <&camera_pins_cam2_rst1_1>;
		pinctrl-14 = <&camera_pins_cam2_ponv_0>;
		pinctrl-15 = <&camera_pins_cam2_ponv_1>;
		pinctrl-16 = <&camera_pins_cam2_scl_ap>;
		pinctrl-17 = <&camera_pins_cam2_scl_scp>;
		pinctrl-18 = <&camera_pins_cam2_sda_ap>;
		pinctrl-19 = <&camera_pins_cam2_sda_scp>;
		pinctrl-20 = <&camera_pins_cam2_eint>;
#endif

		avdd-supply = <&rt5133_ldo6>; // AVDD for imx598/imx709
		avdd3-supply = <&camera_common_avdd2>; // AVDD2 for imx866
		avdd4-supply = <&rt5133_gpio2>; // AVDD2 for imx598
		dvdd-supply = <&rt5133_ldo7>; // DVDD for imx598
		dvdd2-supply = <&rt5133_ldo8>; // DVDD for imx709
		afvdd-supply = <&rt5133_ldo2>;
		dovdd-supply = <&camera_common_dovdd>;
		base-supply = <&rt5133_base>;

		clocks = <&cksys_clk CLK_CK_UNIVPLL_192M_D32>,
			<&cksys_clk CLK_CK_UNIVPLL_192M_D16>,
			<&cksys_clk CLK_CK_F26M_CK_D2>,
			<&cksys_clk CLK_CK_UNIVPLL_192M_D10>,
			<&cksys_clk CLK_CK_UNIVPLL_192M_D8>,
			<&cksys_clk CLK_CK_UNIVPLL_D6_D16>,
			<&cksys_clk CLK_CK_OSC3>,
			<&cksys_clk CLK_CK_UNIVPLL_D6_D8>,
			<&vlp_cksys_clk CLK_VLP_CK_CAMTG4_SEL>;
		clock-names = "6", "12", "13", "19.2", "24", "26", "26_ulposc", "52", "mclk";
#if 0
		clock-names = "6", "12", "13", "19.2", "24", "26", "52", "mclk",
			      "clk1_6", "clk1_12", "clk1_13", "clk1_19.2",
			      "clk1_24", "clk1_26", "clk1_26_ulposc", "clk1_52", "clk1_mclk1";
#endif
		status = "okay";
		port {
			sensor2_out: endpoint {
				remote-endpoint = <&seninf_csi_port_4_in_1>;
			};
		};
	};

	mtk_camera_eeprom2:camera-eeprom2@54 {
		compatible = "mediatek,camera_eeprom";
		reg = <0x54>;
		names = "imx598_cust_eeprom";
		status = "okay";
	};
};

#if 0
&i2c6 {
	#address-cells = <1>;
	#size-cells = <0>;
	lm3643:lm3643@63 {
		compatible = "mediatek,lm3643";
		#address-cells = <1>;
		#size-cells = <0>;
		reg = <0x63>;
		#cooling-cells = <2>;
		pinctrl-names = "default", "hwen-high", "hwen-low";
		pinctrl-0 = <&lm3643_pins_default>;
		pinctrl-1 = <&lm3643_pins_hwen_high>;
		pinctrl-2 = <&lm3643_pins_hwen_low>;
		status = "okay";
		vin = <3600>;
		state-current = <150000 100000 50000 25000>;
		flash@0{
			reg = <0>;
			type = <0>;
			ct = <0>;
			part = <0>;
			port {
				fl_core_0: endpoint {
					remote-endpoint = <&flashlight_0>;
				};
			};
		};
		flash@1{
			reg = <1>;
			type = <0>;
			ct = <1>;
			part = <0>;
			port {
				fl_core_1: endpoint {
					remote-endpoint = <&flashlight_1>;
				};
			};
		};
	};
};

&pio {
	lm3643_pins_default: default {
	};

	lm3643_pins_hwen_high: hwen-high {
		pins-cmd-dat {
			pinmux = <PINMUX_GPIO7__FUNC_GPIO7>;
			slew-rate = <1>;
			output-high;
		};
	};

	lm3643_pins_hwen_low: hwen-low {
		pins-cmd-dat {
			pinmux = <PINMUX_GPIO7__FUNC_GPIO7>;
			slew-rate = <1>;
			output-low;
		};
	};
};

&mtk_composite_v4l2_1 {
	#address-cells = <1>;
	#size-cells = <0>;
	port@0 {
		reg = <0>;
		flashlight_0: endpoint {
			remote-endpoint = <&fl_core_0>;
		};
	};
	port@1 {
		reg = <1>;
		flashlight_1: endpoint {
			remote-endpoint = <&fl_core_1>;
		};
	};
};
#endif
&thermal_zones {
	camera0: camera0 {
		polling-delay = <0>;
		polling-delay-passive = <0>;
		thermal-sensors = <&sensor0>;
		trips {
			camera0_crit: camera0-crit {
				temperature = <120000>;
				hysteresis = <2000>;
				type = "passive";
			};
		};
	};
	camera1: camera1 {
		polling-delay = <0>;
		polling-delay-passive = <0>;
		thermal-sensors = <&sensor1>;
		trips {
			camera1_crit: camera1-crit {
				temperature = <120000>;
				hysteresis = <2000>;
				type = "passive";
			};
		};
	};
	camera2: camera2 {
		polling-delay = <0>;
		polling-delay-passive = <0>;
		thermal-sensors = <&sensor2>;
		trips {
			camera2_crit: camera2-crit {
				temperature = <120000>;
				hysteresis = <2000>;
				type = "passive";
			};
		};
	};
	camera4: camera4 {
		polling-delay = <0>;
		polling-delay-passive = <0>;
		thermal-sensors = <&sensor4>;
		trips {
			camera4_crit: camera4-crit {
				temperature = <120000>;
				hysteresis = <2000>;
				type = "passive";
			};
		};
	};
	camera6: camera6 {
		polling-delay = <0>;
		polling-delay-passive = <0>;
		thermal-sensors = <&sensor6>;
		trips {
			camera6_crit: camera6-crit {
				temperature = <120000>;
				hysteresis = <2000>;
				type = "passive";
			};
		};
	};
	camera7: camera7 {
		polling-delay = <0>;
		polling-delay-passive = <0>;
		thermal-sensors = <&sensor7>;
		trips {
			camera7_crit: camera7-crit {
				temperature = <120000>;
				hysteresis = <2000>;
				type = "passive";
			};
		};
	};
	camera8: camera8 {
		polling-delay = <0>;
		polling-delay-passive = <0>;
		thermal-sensors = <&sensor8>;
		trips {
			camera8_crit: camera8-crit {
				temperature = <120000>;
				hysteresis = <2000>;
				type = "passive";
			};
		};
	};
};
